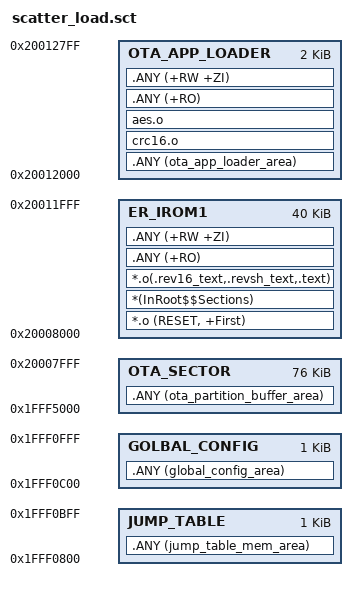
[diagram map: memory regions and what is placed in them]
; *************************************************************
; *** Scatter-Loading Description File generated by uVision ***
; *************************************************************

 LR_IROM1 0x20008000 0x0000a000 {  ; load region size_region
  ER_IROM1 0x20008000 0x0000a000  {  ; load address = execution address
   *.o (RESET, +First)
   *(InRoot$$Sections)
   *.o(.rev16_text,.revsh_text,.text)
   .ANY (+RO) 
   .ANY (+RW +ZI) 
  }
  
  ;RW_IRAM1 0x20000000 0x00003000  {  ; RW data
  ; .ANY (+RW +ZI)
  ;}
  ;ER_IROM2 0x1fff4100 0x0003500  {  ; load address = execution address
  ; .ANY (+RO) 
  ;}  
  
  ;RW_IRAM1 0x1fff7600 0x00000d00  {  ; RW data
  ; .ANY (+RW +ZI)
  ;}
 
}
 
LR_IROM2  0x1fff5000 0x13000 {
  OTA_SECTOR 0x1fff5000 0x13000  {
   .ANY (ota_partition_buffer_area) 
	
  }
 } 

LR_IROM3  0x1fff0800 0x00800 {
  JUMP_TABLE 0x1fff0800 0x00400  {
   .ANY (jump_table_mem_area) 
	
  }
  GOLBAL_CONFIG 0x1fff0c00 0x00400  {
   .ANY (global_config_area) 
	
  }  
 } 
LR_IROM4  0x20012000 0x800 {
  OTA_APP_LOADER 0x20012000 0x800  {
   .ANY (ota_app_loader_area) 
   crc16.o
   aes.o
   .ANY (+RO) 
   .ANY (+RW +ZI) 
	
  }
 } 


